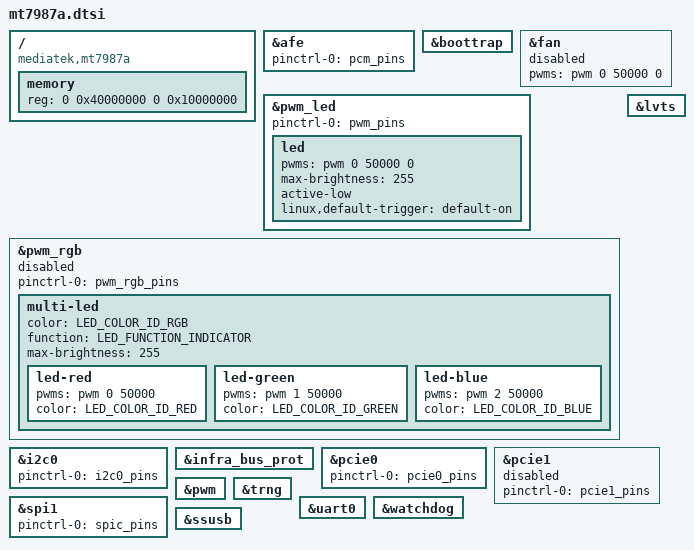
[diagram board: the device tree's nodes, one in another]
// SPDX-License-Identifier: (GPL-2.0 OR MIT)
/*
 * Copyright (C) 2023 MediaTek Inc.
 * Author: Sam.Shih <sam.shih@mediatek.com>
 */

/dts-v1/;
#include <dt-bindings/leds/common.h>
#include "mt7987.dtsi"
#include "mt7987-pinctrl.dtsi"
#include "mt7987-netsys.dtsi"

/ {
	compatible = "mediatek,mt7987a", "mediatek,mt7987";

	memory {
		reg = <0 0x40000000 0 0x10000000>;
	};

};

&afe {
	pinctrl-names = "default";
	pinctrl-0 = <&pcm_pins>;
	status = "okay";
};

&boottrap {
	status = "okay";
};

&fan {
	pwms = <&pwm 0 50000 0>;
	status = "disabled";
};

/* use pwm0 as led: share with fan/pwm_rgb */
&pwm_led {
	pinctrl-names = "default";
	pinctrl-0 = <&pwm_pins>;
	status = "okay";

	led {
		pwms = <&pwm 0 50000 0>;
		max-brightness = <255>;
		active-low;
		linux,default-trigger = "default-on";
	};
};

/* use pwm0/1/2 as multicolor LED: share with fan/pwm_led */
&pwm_rgb {
	pinctrl-names = "default";
	pinctrl-0 = <&pwm_rgb_pins>;
	status = "disabled";

	multi-led {
		color = <LED_COLOR_ID_RGB>;
		function = LED_FUNCTION_INDICATOR;
		max-brightness = <255>;

		led-red {
			pwms = <&pwm 0 50000>;
			color = <LED_COLOR_ID_RED>;
		};

		led-green {
			pwms = <&pwm 1 50000>;
			color = <LED_COLOR_ID_GREEN>;
		};

		led-blue {
			pwms = <&pwm 2 50000>;
			color = <LED_COLOR_ID_BLUE>;
		};
	};
};

&i2c0 {
	pinctrl-names = "default";
	pinctrl-0 = <&i2c0_pins>;
	status = "okay";
};

&infra_bus_prot {
	status = "okay";
};

&lvts {
	status = "okay";
};

&pcie0 {
	pinctrl-names = "default";
	pinctrl-0 = <&pcie0_pins>;
	status = "okay";
};

&pcie1 {
	pinctrl-names = "default";
	pinctrl-0 = <&pcie1_pins>;
	status = "disabled";
};

&pwm {
	status = "okay";
};

&spi1 {
	pinctrl-names = "default";
	pinctrl-0 = <&spic_pins>;
	status = "okay";
};

&trng {
	status = "okay";
};

&uart0 {
	status = "okay";
};

&watchdog {
	status = "okay";
};

&ssusb {
	status = "okay";
};
